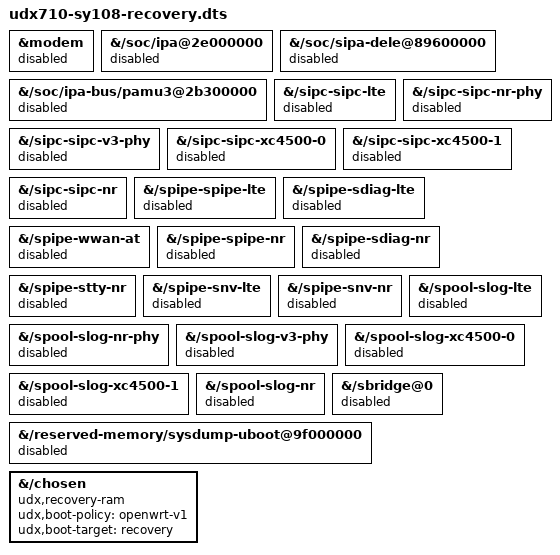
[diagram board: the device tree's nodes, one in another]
// SPDX-License-Identifier: GPL-2.0-only
/* Independent SY108 RAM Recovery. */
/dts-v1/;
#include "udx710-sy108.dtsi"
/* Independent RAM Recovery has no cellular data, NV, CP/DSP loader or CP log
 * consumer. PM_SYS is a platform dependency: preserve SIPC dst6, its mailbox,
 * PM control/log pipes, UART proxy/MCU, DDR, USB, NAND and all reserved memory.
 * Other unused controllers keep their common disabled state.
 */
&modem {
	status = "disabled";
};
&{/soc/ipa@2e000000} {
	status = "disabled";
};
&{/soc/sipa-dele@89600000} {
	status = "disabled";
};
&{/soc/ipa-bus/pamu3@2b300000} {
	status = "disabled";
};
&{/sipc-sipc-lte} {
	status = "disabled";
};
&{/sipc-sipc-nr-phy} {
	status = "disabled";
};
&{/sipc-sipc-v3-phy} {
	status = "disabled";
};
&{/sipc-sipc-xc4500-0} {
	status = "disabled";
};
&{/sipc-sipc-xc4500-1} {
	status = "disabled";
};
&{/sipc-sipc-nr} {
	status = "disabled";
};
&{/spipe-spipe-lte} {
	status = "disabled";
};
&{/spipe-sdiag-lte} {
	status = "disabled";
};
&{/spipe-wwan-at} {
	status = "disabled";
};
&{/spipe-spipe-nr} {
	status = "disabled";
};
&{/spipe-sdiag-nr} {
	status = "disabled";
};
&{/spipe-stty-nr} {
	status = "disabled";
};
&{/spipe-snv-lte} {
	status = "disabled";
};
&{/spipe-snv-nr} {
	status = "disabled";
};
&{/spool-slog-lte} {
	status = "disabled";
};
&{/spool-slog-nr-phy} {
	status = "disabled";
};
&{/spool-slog-v3-phy} {
	status = "disabled";
};
&{/spool-slog-xc4500-0} {
	status = "disabled";
};
&{/spool-slog-xc4500-1} {
	status = "disabled";
};
&{/spool-slog-nr} {
	status = "disabled";
};
&{/sbridge@0} {
	status = "disabled";
};
/* The installed U-Boot fixup reduces this optional dump reservation to size zero.
 * Recovery uses the separate CRC-checked kernel log, not U-Boot RAM dumping.
 */
&{/reserved-memory/sysdump-uboot@9f000000} {
	status = "disabled";
};
&{/chosen} {
	udx,recovery-ram;
	udx,boot-policy = "openwrt-v1";
	udx,boot-target = "recovery";
};
